VERSION ""

NS_ :

BS_:

BU_: CGW SCCM RDF ECM IC ACC ESP

BO_ 1046 NM_SCCM: 2 SCCM
 SG_ NM_SCCM_State : 8|8@1+ (1,0) [0|32] ""  RDF,IC,ESP,ECM,CGW,ACC
 SG_ NM_SCCM_ID : 0|8@1- (1,0) [0|0] ""  RDF,IC,ESP,ECM,CGW,ACC

BO_ 1045 NM_RDF: 2 RDF
 SG_ NM_RDF_State : 8|8@1+ (1,0) [0|32] ""  SCCM,RDF,IC,ESP,ECM,CGW,ACC
 SG_ NM_RDF_ID : 0|8@1+ (1,0) [0|255] ""  SCCM,RDF,IC,ESP,ECM,CGW,ACC

BO_ 1044 NM_IC: 2 IC
 SG_ NM_IC_State : 8|8@1+ (1,0) [0|32] ""  SCCM,RDF,ESP,ECM,CGW,ACC
 SG_ NM_IC_ID : 0|8@1+ (1,0) [0|255] ""  SCCM,RDF,ESP,ECM,CGW,ACC

BO_ 1029 NM_ESP: 2 ESP
 SG_ NM_ESP_State : 8|8@1+ (1,0) [0|32] ""  SCCM,RDF,IC,ECM,CGW,ACC
 SG_ NM_ESP_ID : 0|8@1+ (1,0) [0|255] ""  SCCM,RDF,IC,ECM,CGW,ACC

BO_ 1034 NM_ECM: 2 ECM
 SG_ NM_ECM_State : 8|8@1+ (1,0) [0|32] ""  SCCM,RDF,IC,ESP,ECM,CGW,ACC
 SG_ NM_ECM_ID : 0|8@1+ (1,0) [0|255] ""  SCCM,RDF,IC,ESP,ECM,CGW,ACC

BO_ 1024 NM_CGW: 2 CGW
 SG_ NM_CGW_State : 8|8@1+ (1,0) [0|32] ""  SCCM,RDF,IC,ESP,ECM,ACC
 SG_ NM_CGW_ID : 0|8@1+ (1,0) [0|255] ""  SCCM,RDF,IC,ESP,ECM,ACC

BO_ 1039 NM_ACC: 2 ACC
 SG_ NM_ACC_State : 8|8@1+ (1,0) [0|32] ""  SCCM,RDF,IC,ESP,ECM,CGW
 SG_ NM_ACC_ID : 0|8@1+ (1,0) [0|255] ""  SCCM,RDF,IC,ESP,ECM,CGW

BO_ 848 ECM_DIAG_RS_E2E_PR1: 32 ECM
 SG_ CAN_Frame_03_Signal_CRC : 0|8@1+ (1,0) [0|255] ""  CGW
 SG_ CAN_Frame_03_Signal_MC : 8|4@1+ (1,0) [0|15] ""  CGW
 SG_ CAN_Frame_03_Signal_I : 209|1@1+ (1,0) [0|1] ""  CGW
 SG_ CAN_Frame_03_Signal_H : 208|1@1+ (1,0) [0|1] ""  CGW
 SG_ CAN_Frame_03_Signal_G : 176|32@1- (1,0) [-2147483648|2147483647] ""  CGW
 SG_ CAN_Frame_03_Signal_F : 144|32@1- (1,0) [-2147483648|2147483647] ""  CGW
 SG_ CAN_Frame_03_Signal_E : 112|32@1- (1,0) [-2147483648|2147483647] ""  CGW
 SG_ CAN_Frame_03_Signal_D : 80|32@1- (1,0) [-2147483648|2147483647] ""  CGW
 SG_ CAN_Frame_03_Signal_C : 48|32@1- (1,0) [-2147483648|2147483647] ""  CGW
 SG_ CAN_Frame_03_Signal_B : 16|32@1- (0.1,0) [-214748364.8|214748364.7] "V"  CGW
 SG_ CAN_Frame_03_Signal_A : 12|4@1+ (1,0) [0|15] ""  CGW

BO_ 832 CGW_DIAG_RQ_E2E_PR1: 32 CGW
 SG_ CAN_Frame_02_Signal_MC : 8|4@1+ (1,0) [0|15] ""  SCCM,RDF,IC,ESP,ECM,ACC
 SG_ CAN_Frame_02_Signal_CRC : 0|8@1+ (1,0) [0|255] ""  SCCM,RDF,IC,ESP,ECM,ACC
 SG_ CAN_Frame_02_Signal_I : 209|1@1+ (1,0) [0|1] ""  SCCM,RDF,IC,ESP,ECM,ACC
 SG_ CAN_Frame_02_Signal_H : 208|1@1+ (1,0) [0|1] ""  SCCM,RDF,IC,ESP,ECM,ACC
 SG_ CAN_Frame_02_Signal_G : 176|32@1- (1,0) [-2147483648|2147483647] ""  SCCM,RDF,IC,ESP,ECM,ACC
 SG_ CAN_Frame_02_Signal_F : 144|32@1- (1,0) [-2147483648|2147483647] ""  SCCM,RDF,IC,ESP,ECM,ACC
 SG_ CAN_Frame_02_Signal_E : 112|32@1- (1,0) [-2147483648|2147483647] ""  SCCM,RDF,IC,ESP,ECM,ACC
 SG_ CAN_Frame_02_Signal_D : 80|32@1- (1,0) [-2147483648|2147483647] ""  SCCM,RDF,IC,ESP,ECM,ACC
 SG_ CAN_Frame_02_Signal_C : 48|32@1- (1,0) [-2147483648|2147483647] ""  SCCM,RDF,IC,ESP,ECM,ACC
 SG_ CAN_Frame_02_Signal_B : 16|32@1- (0.1,0) [-214748364.8|214748364.7] "V"  SCCM,RDF,IC,ESP,ECM,ACC
 SG_ CAN_Frame_02_Signal_A : 12|4@1+ (1,0) [0|15] ""  SCCM,RDF,IC,ESP,ECM,ACC

BO_ 801 CGW_DIAG_E2E_PR1: 32 CGW
 SG_ CAN_Frame_01_Signal_G : 192|32@1- (1,0) [-2147483648|2147483647] ""  SCCM,RDF,IC,ESP,ECM,ACC
 SG_ CAN_Frame_01_Signal_F : 160|32@1- (1,0) [-2147483648|2147483647] ""  SCCM,RDF,IC,ESP,ECM,ACC
 SG_ CAN_Frame_01_Signal_E : 128|32@1- (1,0) [-2147483648|2147483647] ""  SCCM,RDF,IC,ESP,ECM,ACC
 SG_ CAN_Frame_01_Signal_D : 96|32@1- (1,0) [-2147483648|2147483647] ""  SCCM,RDF,IC,ESP,ECM,ACC
 SG_ CAN_Frame_01_Signal_MC : 8|4@1+ (1,0) [0|15] ""  SCCM,RDF,IC,ESP,ECM,ACC
 SG_ CAN_Frame_01_Signal_CRC : 0|8@1+ (1,0) [0|255] ""  SCCM,RDF,IC,ESP,ECM,ACC
 SG_ CAN_Frame_01_Signal_C : 64|32@1- (1,0) [-2147483648|2147483647] ""  SCCM,RDF,IC,ESP,ECM,ACC
 SG_ CAN_Frame_01_Signal_B : 32|32@1- (0.1,0) [-214748364.8|214748364.7] "V"  SCCM,RDF,IC,ESP,ECM,ACC
 SG_ CAN_Frame_01_Signal_A : 16|16@1+ (1,0) [0|65535] ""  SCCM,RDF,IC,ESP,ECM,ACC

BO_ 315 SCCM_ACC_E2E_PR2: 12 SCCM
 SG_ SCCM_ACC_E2E_PR2_MC : 8|4@1+ (1,0) [0|15] ""  ACC
 SG_ SCCM_ACC_E2E_PR2_CRC : 0|8@1+ (1,0) [0|255] ""  ACC
 SG_ SCCM_st_ACCSpdUp10 : 72|8@1- (1,0) [0|0] ""  ACC
 SG_ SCCM_st_ACCSpdUp1 : 64|8@1+ (1,0) [0|0] ""  ACC
 SG_ SCCM_st_ACCSpdDn10 : 56|8@1- (1,0) [0|0] ""  ACC
 SG_ SCCM_st_ACCSpdDn1 : 48|8@1- (1,0) [0|0] ""  ACC
 SG_ SCCM_st_ACCDistUpRq : 40|8@1+ (1,0) [0|0] ""  ACC
 SG_ SCCM_st_ACCDistDnRq : 32|8@1- (1,0) [0|0] ""  ACC
 SG_ SCCM_st_ACCResume : 24|8@1+ (1,0) [0|3] ""  ACC
 SG_ SCCM_st_ACCOn : 16|8@1+ (1,0) [0|3] ""  ACC

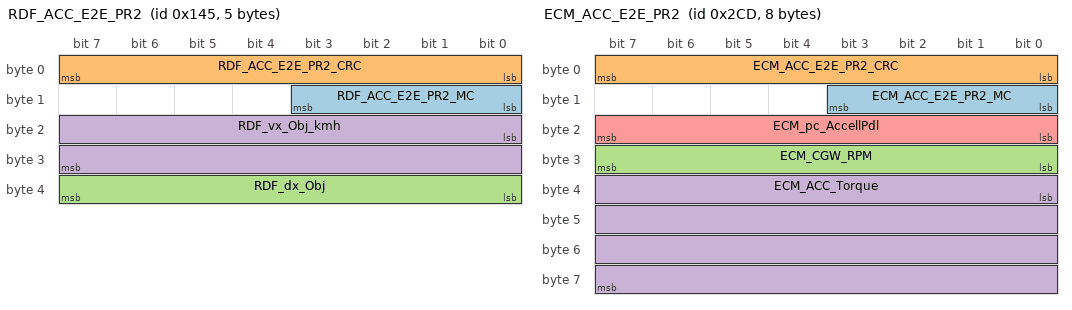
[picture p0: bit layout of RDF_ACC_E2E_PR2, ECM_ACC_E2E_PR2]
BO_ 325 RDF_ACC_E2E_PR2: 5 RDF
 SG_ RDF_ACC_E2E_PR2_MC : 8|4@1+ (1,0) [0|15] ""  ACC
 SG_ RDF_ACC_E2E_PR2_CRC : 0|8@1+ (1,0) [0|255] ""  ACC
 SG_ RDF_dx_Obj : 32|8@1+ (1,0) [0|255] "m"  ACC
 SG_ RDF_vx_Obj_kmh : 16|16@1+ (1,0) [0|255] "km/h"  ACC

BO_ 717 ECM_ACC_E2E_PR2: 8 ECM
 SG_ ECM_ACC_E2E_PR2_MC : 8|4@1+ (1,0) [0|15] ""  ACC
 SG_ ECM_ACC_E2E_PR2_CRC : 0|8@1+ (1,0) [0|255] ""  ACC
 SG_ ECM_CGW_RPM : 24|8@1+ (1,0) [0|10000] ""  CGW,ACC
 SG_ ECM_ACC_Torque : 32|32@1- (1,0) [-2147483648|2147483647] "Nm"  ACC
 SG_ ECM_pc_AccellPdl : 16|8@1- (1,0) [0|0] ""  ACC

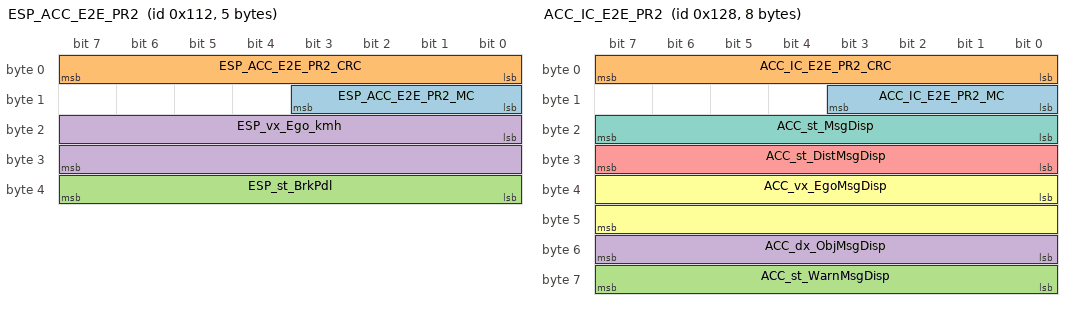
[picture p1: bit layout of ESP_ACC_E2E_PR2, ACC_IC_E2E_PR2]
BO_ 274 ESP_ACC_E2E_PR2: 5 ESP
 SG_ ESP_ACC_E2E_PR2_MC : 8|4@1+ (1,0) [0|15] ""  ACC
 SG_ ESP_ACC_E2E_PR2_CRC : 0|8@1+ (1,0) [0|255] ""  ACC
 SG_ ESP_st_BrkPdl : 32|8@1- (1,0) [0|0] ""  ACC
 SG_ ESP_vx_Ego_kmh : 16|16@1- (1,0) [0|255] ""  ACC

BO_ 296 ACC_IC_E2E_PR2: 8 ACC
 SG_ ACC_IC_E2E_PR2_MC : 8|4@1+ (1,0) [0|15] ""  IC
 SG_ ACC_IC_E2E_PR2_CRC : 0|8@1+ (1,0) [0|255] ""  IC
 SG_ ACC_st_WarnMsgDisp : 56|8@1- (1,0) [0|0] ""  IC
 SG_ ACC_dx_ObjMsgDisp : 48|8@1+ (1,0) [0|255] "m"  SCCM,IC
 SG_ ACC_st_DistMsgDisp : 24|8@1+ (1,0) [0|6] ""  IC
 SG_ ACC_vx_EgoMsgDisp : 32|16@1- (1,0) [0|0] ""  IC
 SG_ ACC_st_MsgDisp : 16|8@1+ (1,0) [0|4] ""  IC

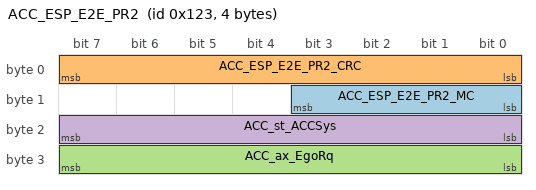
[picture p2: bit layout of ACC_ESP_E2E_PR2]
BO_ 291 ACC_ESP_E2E_PR2: 4 ACC
 SG_ ACC_ESP_E2E_PR2_MC : 8|4@1+ (1,0) [0|15] ""  ESP
 SG_ ACC_ESP_E2E_PR2_CRC : 0|8@1+ (1,0) [0|255] ""  ESP
 SG_ ACC_ax_EgoRq : 24|8@1- (1,0) [0|0] ""  ESP
 SG_ ACC_st_ACCSys : 16|8@1+ (1,0) [0|4] ""  ESP

CM_ "This example is generated by AKKA Gmbh& Co. KGaA for PROVEtech:RBS";
CM_ SG_ 848 CAN_Frame_03_Signal_CRC "CRC-Checksum according SAE J1850";
CM_ SG_ 848 CAN_Frame_03_Signal_MC "Messagecounter";
CM_ SG_ 832 CAN_Frame_02_Signal_MC "Messagecounter";
CM_ SG_ 832 CAN_Frame_02_Signal_CRC "CRC-Checksum according SAE J1850";
CM_ SG_ 801 CAN_Frame_01_Signal_MC "Messagecounter";
CM_ SG_ 801 CAN_Frame_01_Signal_CRC "CRC-Checksum according SAE J1850";
BA_DEF_  "Baudrate" INT 1 1000000;
BA_DEF_ BO_  "GenMsgChkConstant" HEX 0 4095;
BA_DEF_ BO_  "CANFD_BRS" ENUM  "0","1";
BA_DEF_  "Manufacturer" STRING ;
BA_DEF_  "NmMessageCount" INT 0 1024;
BA_DEF_ BU_  "NmStationAddress" INT 0 128;
BA_DEF_ BU_  "NmNode" ENUM  "no","yes";
BA_DEF_ BO_  "NmMessage" ENUM  "no","yes";
BA_DEF_  "NmBaseAddress" HEX 1024 1152;
BA_DEF_ BO_  "GenMsgCycleTimeFast" INT 0 16384;
BA_DEF_ BO_  "GenMsgPDUConstants" STRING ;
BA_DEF_  "Version_Year" INT 0 40;
BA_DEF_  "Version_Week" INT 1 52;
BA_DEF_  "Version_Month" INT 1 12;
BA_DEF_  "Version_Day" INT 1 31;
BA_DEF_  "DBName" STRING ;
BA_DEF_  "BusType" STRING ;
BA_DEF_ BO_  "VFrameFormat" ENUM  "StandardCAN","ExtendedCAN","reserved","J1939PG","reserved","reserved","reserved","reserved","reserved","reserved","reserved","reserved","reserved","reserved","StandardCAN_FD","ExtendedCAN_FD";
BA_DEF_ BO_  "GenMsgSendType" ENUM  "cyclicX","spontanX","cyclicIfActiveX","spontanWithDelay","cyclicAndSpontanX","cyclicAndSpontanWithDelay","spontanWithRepitition","cyclicIfActiveAndSpontanWD","cyclicIfActiveFast","cyclicWithRepeatOnDemand","none";
BA_DEF_ BO_  "GenMsgCycleTime" INT 0 65535;
BA_DEF_ BO_  "GenMsgDelayTime" INT 0 65535;
BA_DEF_ SG_  "GenSigStartValue" FLOAT 0 0;
BA_DEF_ SG_  "FlexKomSigName" STRING ;
BA_DEF_DEF_  "Baudrate" 1;
BA_DEF_DEF_  "GenMsgChkConstant" 0;
BA_DEF_DEF_  "CANFD_BRS" "1";
BA_DEF_DEF_  "Manufacturer" "AKKA GmbH & Co. KGaA";
BA_DEF_DEF_  "NmMessageCount" 1;
BA_DEF_DEF_  "NmStationAddress" 0;
BA_DEF_DEF_  "NmNode" "no";
BA_DEF_DEF_  "NmMessage" "no";
BA_DEF_DEF_  "NmBaseAddress" 1024;
BA_DEF_DEF_  "GenMsgCycleTimeFast" 0;
BA_DEF_DEF_  "GenMsgPDUConstants" "";
BA_DEF_DEF_  "Version_Year" 19;
BA_DEF_DEF_  "Version_Week" 1;
BA_DEF_DEF_  "Version_Month" 1;
BA_DEF_DEF_  "Version_Day" 1;
BA_DEF_DEF_  "DBName" "CAN_Demo_Box_Cluster";
BA_DEF_DEF_  "BusType" "CAN";
BA_DEF_DEF_  "VFrameFormat" "StandardCAN";
BA_DEF_DEF_  "GenMsgSendType" "cyclicX";
BA_DEF_DEF_  "GenMsgCycleTime" 0;
BA_DEF_DEF_  "GenMsgDelayTime" 0;
BA_DEF_DEF_  "GenSigStartValue" 0;
BA_DEF_DEF_  "FlexKomSigName" "";
BA_ "BusType" "CAN FD";
BA_ "NmMessageCount" 256;
BA_ "Baudrate" 500000;
BA_ "DBName" "ACC_Demo";
BA_ "NmNode" BU_ CGW 1;
BA_ "NmNode" BU_ SCCM 1;
BA_ "NmStationAddress" BU_ SCCM 22;
BA_ "NmNode" BU_ RDF 1;
BA_ "NmStationAddress" BU_ RDF 21;
BA_ "NmNode" BU_ ECM 1;
BA_ "NmStationAddress" BU_ ECM 10;
BA_ "NmNode" BU_ IC 1;
BA_ "NmStationAddress" BU_ IC 20;
BA_ "NmNode" BU_ ACC 1;
BA_ "NmStationAddress" BU_ ACC 15;
BA_ "NmNode" BU_ ESP 1;
BA_ "NmStationAddress" BU_ ESP 5;
BA_ "GenMsgSendType" BO_ 1046 1;
BA_ "NmMessage" BO_ 1046 1;
BA_ "VFrameFormat" BO_ 1046 14;
BA_ "NmMessage" BO_ 1045 1;
BA_ "GenMsgSendType" BO_ 1045 1;
BA_ "VFrameFormat" BO_ 1045 14;
BA_ "NmMessage" BO_ 1044 1;
BA_ "GenMsgSendType" BO_ 1044 1;
BA_ "VFrameFormat" BO_ 1044 14;
BA_ "NmMessage" BO_ 1029 1;
BA_ "GenMsgSendType" BO_ 1029 1;
BA_ "VFrameFormat" BO_ 1029 14;
BA_ "NmMessage" BO_ 1034 1;
BA_ "GenMsgSendType" BO_ 1034 1;
BA_ "VFrameFormat" BO_ 1034 14;
BA_ "NmMessage" BO_ 1024 1;
BA_ "GenMsgSendType" BO_ 1024 1;
BA_ "VFrameFormat" BO_ 1024 14;
BA_ "GenMsgSendType" BO_ 1039 1;
BA_ "NmMessage" BO_ 1039 1;
BA_ "VFrameFormat" BO_ 1039 14;
BA_ "GenMsgPDUConstants" BO_ 848 "0x11,0x11,0x11,0x11,0x11,0x11,0x11,0x11,0x11,0x11,0x11,0x11,0x11,0x11,0x11,0x11";
BA_ "GenMsgSendType" BO_ 848 5;
BA_ "GenMsgCycleTime" BO_ 848 500;
BA_ "GenMsgDelayTime" BO_ 848 20;
BA_ "GenMsgChkConstant" BO_ 848 17;
BA_ "VFrameFormat" BO_ 848 14;
BA_ "GenMsgPDUConstants" BO_ 832 "0x42,0x42,0x42,0x42,0x42,0x42,0x42,0x42,0x42,0x42,0x42,0x42,0x42,0x42,0x42,0x42";
BA_ "GenMsgSendType" BO_ 832 4;
BA_ "GenMsgCycleTime" BO_ 832 1000;
BA_ "GenMsgChkConstant" BO_ 832 66;
BA_ "GenMsgCycleTimeFast" BO_ 832 100;
BA_ "GenMsgDelayTime" BO_ 832 20;
BA_ "VFrameFormat" BO_ 832 14;
BA_ "GenMsgCycleTime" BO_ 801 100;
BA_ "GenMsgSendType" BO_ 801 5;
BA_ "GenMsgCycleTimeFast" BO_ 801 50;
BA_ "GenMsgPDUConstants" BO_ 801 "0x90,0x90,0x90,0x90,0x90,0x90,0x90,0x90,0x90,0x90,0x90,0x90,0x90,0x90,0x90,0x90";
BA_ "GenMsgChkConstant" BO_ 801 144;
BA_ "GenMsgDelayTime" BO_ 801 5;
BA_ "VFrameFormat" BO_ 801 14;
BA_ "GenMsgPDUConstants" BO_ 315 "0x34,0x56,0x29,0x59,0x79,0x82,0xAD,0x22,0x61,0x81,0x78,0x23,0x72,0xA3,0x26,0x04";
BA_ "GenMsgSendType" BO_ 315 5;
BA_ "GenMsgCycleTime" BO_ 315 20;
BA_ "GenMsgDelayTime" BO_ 315 10;
BA_ "VFrameFormat" BO_ 315 14;
BA_ "GenMsgPDUConstants" BO_ 325 "0x82,0x29,0x43,0x89,0x89,0x12,0xAD,0x22,0x61,0x81,0x89,0x18,0x23,0x48,0x78,0x52";
BA_ "GenMsgCycleTime" BO_ 325 10;
BA_ "GenMsgDelayTime" BO_ 325 5;
BA_ "VFrameFormat" BO_ 325 14;
BA_ "GenMsgCycleTimeFast" BO_ 717 20;
BA_ "GenMsgPDUConstants" BO_ 717 "0x79,0x62,0x533,0x99,0x89,0x13,0xAD,0x22,0x61,0x81,0x78,0x23,0x72,0xA8,0x76,0x09";
BA_ "GenMsgSendType" BO_ 717 5;
BA_ "GenMsgCycleTime" BO_ 717 50;
BA_ "GenMsgDelayTime" BO_ 717 10;
BA_ "VFrameFormat" BO_ 717 14;
BA_ "GenMsgCycleTimeFast" BO_ 274 10;
BA_ "GenMsgPDUConstants" BO_ 274 "0x94,0x27,0x73,0x92,0x49,0x12,0xAD,0x22,0x61,0x81,0x78,0x23,0x72,0x13,0x21,0x22";
BA_ "GenMsgSendType" BO_ 274 5;
BA_ "GenMsgCycleTime" BO_ 274 20;
BA_ "GenMsgDelayTime" BO_ 274 5;
BA_ "VFrameFormat" BO_ 274 14;
BA_ "GenMsgPDUConstants" BO_ 296 "0x59,0x67,0x53,0x89,0x89,0x12,0xAD,0x22,0x61,0x81,0x78,0x23,0x72,0xA3,0x26,0x04";
BA_ "GenMsgCycleTimeFast" BO_ 296 50;
BA_ "GenMsgSendType" BO_ 296 5;
BA_ "GenMsgCycleTime" BO_ 296 100;
BA_ "GenMsgDelayTime" BO_ 296 10;
BA_ "VFrameFormat" BO_ 296 14;
BA_ "GenMsgCycleTimeFast" BO_ 291 100;
BA_ "GenMsgPDUConstants" BO_ 291 "0x65,0x16,0x53,0x89,0x65,0x02,0xCD,0x22,0x61,0x81,0x14,0x23,0x78,0xA1,0x23,0x03";
BA_ "GenMsgSendType" BO_ 291 8;
BA_ "GenMsgCycleTime" BO_ 291 1000;
BA_ "VFrameFormat" BO_ 291 14;
BA_ "FlexKomSigName" SG_ 848 CAN_Frame_03_Signal_CRC "CAN_Frame_03_SignalGroup";
BA_ "GenSigStartValue" SG_ 848 CAN_Frame_03_Signal_CRC 255;
BA_ "FlexKomSigName" SG_ 848 CAN_Frame_03_Signal_MC "CAN_Frame_03_SignalGroup";
BA_ "GenSigStartValue" SG_ 848 CAN_Frame_03_Signal_I 1;
BA_ "FlexKomSigName" SG_ 848 CAN_Frame_03_Signal_I "CAN_Frame_03_SignalGroup";
BA_ "GenSigStartValue" SG_ 848 CAN_Frame_03_Signal_H 1;
BA_ "FlexKomSigName" SG_ 848 CAN_Frame_03_Signal_H "CAN_Frame_03_SignalGroup";
BA_ "GenSigStartValue" SG_ 848 CAN_Frame_03_Signal_G 63;
BA_ "FlexKomSigName" SG_ 848 CAN_Frame_03_Signal_G "CAN_Frame_03_SignalGroup";
BA_ "GenSigStartValue" SG_ 848 CAN_Frame_03_Signal_F 255;
BA_ "FlexKomSigName" SG_ 848 CAN_Frame_03_Signal_F "CAN_Frame_03_SignalGroup";
BA_ "GenSigStartValue" SG_ 848 CAN_Frame_03_Signal_E 255;
BA_ "FlexKomSigName" SG_ 848 CAN_Frame_03_Signal_E "CAN_Frame_03_SignalGroup";
BA_ "GenSigStartValue" SG_ 848 CAN_Frame_03_Signal_D 255;
BA_ "FlexKomSigName" SG_ 848 CAN_Frame_03_Signal_D "CAN_Frame_03_SignalGroup";
BA_ "GenSigStartValue" SG_ 848 CAN_Frame_03_Signal_C 255;
BA_ "FlexKomSigName" SG_ 848 CAN_Frame_03_Signal_C "CAN_Frame_03_SignalGroup";
BA_ "GenSigStartValue" SG_ 848 CAN_Frame_03_Signal_B 255;
BA_ "FlexKomSigName" SG_ 848 CAN_Frame_03_Signal_B "CAN_Frame_03_SignalGroup";
BA_ "GenSigStartValue" SG_ 848 CAN_Frame_03_Signal_A 15;
BA_ "FlexKomSigName" SG_ 848 CAN_Frame_03_Signal_A "CAN_Frame_03_SignalGroup";
BA_ "FlexKomSigName" SG_ 832 CAN_Frame_02_Signal_MC "CAN_Frame_02_SignalGroup";
BA_ "FlexKomSigName" SG_ 832 CAN_Frame_02_Signal_CRC "CAN_Frame_02_SignalGroup";
BA_ "GenSigStartValue" SG_ 832 CAN_Frame_02_Signal_CRC 255;
BA_ "GenSigStartValue" SG_ 832 CAN_Frame_02_Signal_I 1;
BA_ "FlexKomSigName" SG_ 832 CAN_Frame_02_Signal_I "CAN_Frame_02_SignalGroup";
BA_ "GenSigStartValue" SG_ 832 CAN_Frame_02_Signal_H 1;
BA_ "FlexKomSigName" SG_ 832 CAN_Frame_02_Signal_H "CAN_Frame_02_SignalGroup";
BA_ "GenSigStartValue" SG_ 832 CAN_Frame_02_Signal_G 63;
BA_ "FlexKomSigName" SG_ 832 CAN_Frame_02_Signal_G "CAN_Frame_02_SignalGroup";
BA_ "GenSigStartValue" SG_ 832 CAN_Frame_02_Signal_F 255;
BA_ "FlexKomSigName" SG_ 832 CAN_Frame_02_Signal_F "CAN_Frame_02_SignalGroup";
BA_ "GenSigStartValue" SG_ 832 CAN_Frame_02_Signal_E 255;
BA_ "FlexKomSigName" SG_ 832 CAN_Frame_02_Signal_E "CAN_Frame_02_SignalGroup";
BA_ "GenSigStartValue" SG_ 832 CAN_Frame_02_Signal_D 255;
BA_ "FlexKomSigName" SG_ 832 CAN_Frame_02_Signal_D "CAN_Frame_02_SignalGroup";
BA_ "GenSigStartValue" SG_ 832 CAN_Frame_02_Signal_C 255;
BA_ "FlexKomSigName" SG_ 832 CAN_Frame_02_Signal_C "CAN_Frame_02_SignalGroup";
BA_ "GenSigStartValue" SG_ 832 CAN_Frame_02_Signal_B 255;
BA_ "FlexKomSigName" SG_ 832 CAN_Frame_02_Signal_B "CAN_Frame_02_SignalGroup";
BA_ "GenSigStartValue" SG_ 832 CAN_Frame_02_Signal_A 15;
BA_ "FlexKomSigName" SG_ 832 CAN_Frame_02_Signal_A "CAN_Frame_02_SignalGroup";
BA_ "GenSigStartValue" SG_ 801 CAN_Frame_01_Signal_G 255;
BA_ "FlexKomSigName" SG_ 801 CAN_Frame_01_Signal_G "CAN_Frame_01_SignalGroup";
BA_ "GenSigStartValue" SG_ 801 CAN_Frame_01_Signal_F 255;
BA_ "FlexKomSigName" SG_ 801 CAN_Frame_01_Signal_F "CAN_Frame_01_SignalGroup";
BA_ "GenSigStartValue" SG_ 801 CAN_Frame_01_Signal_E 255;
BA_ "FlexKomSigName" SG_ 801 CAN_Frame_01_Signal_E "CAN_Frame_01_SignalGroup";
BA_ "GenSigStartValue" SG_ 801 CAN_Frame_01_Signal_D 255;
BA_ "FlexKomSigName" SG_ 801 CAN_Frame_01_Signal_D "CAN_Frame_01_SignalGroup";
BA_ "FlexKomSigName" SG_ 801 CAN_Frame_01_Signal_MC "CAN_Frame_01_SignalGroup";
BA_ "GenSigStartValue" SG_ 801 CAN_Frame_01_Signal_CRC 255;
BA_ "FlexKomSigName" SG_ 801 CAN_Frame_01_Signal_CRC "CAN_Frame_01_SignalGroup";
BA_ "GenSigStartValue" SG_ 801 CAN_Frame_01_Signal_C 255;
BA_ "FlexKomSigName" SG_ 801 CAN_Frame_01_Signal_C "CAN_Frame_01_SignalGroup";
BA_ "GenSigStartValue" SG_ 801 CAN_Frame_01_Signal_B 255;
BA_ "FlexKomSigName" SG_ 801 CAN_Frame_01_Signal_B "CAN_Frame_01_SignalGroup";
BA_ "GenSigStartValue" SG_ 801 CAN_Frame_01_Signal_A 15;
BA_ "FlexKomSigName" SG_ 801 CAN_Frame_01_Signal_A "CAN_Frame_01_SignalGroup";
BA_ "GenSigStartValue" SG_ 315 SCCM_st_ACCSpdUp10 3;
BA_ "GenSigStartValue" SG_ 315 SCCM_st_ACCSpdUp1 3;
BA_ "GenSigStartValue" SG_ 315 SCCM_st_ACCSpdDn10 3;
BA_ "GenSigStartValue" SG_ 315 SCCM_st_ACCSpdDn1 3;
BA_ "GenSigStartValue" SG_ 315 SCCM_st_ACCDistUpRq 3;
BA_ "GenSigStartValue" SG_ 315 SCCM_st_ACCDistDnRq 3;
BA_ "GenSigStartValue" SG_ 315 SCCM_st_ACCResume 3;
BA_ "GenSigStartValue" SG_ 315 SCCM_st_ACCOn 3;
BA_ "GenSigStartValue" SG_ 325 RDF_dx_Obj 255;
BA_ "GenSigStartValue" SG_ 274 ESP_st_BrkPdl 3;
BA_ "GenSigStartValue" SG_ 296 ACC_st_WarnMsgDisp 2;
BA_ "GenSigStartValue" SG_ 296 ACC_st_DistMsgDisp 6;
BA_ "GenSigStartValue" SG_ 296 ACC_st_MsgDisp 3;
BA_ "GenSigStartValue" SG_ 291 ACC_st_ACCSys 3;
VAL_ 1046 NM_SCCM_State 2 "SNA" 1 "Bus sleep" 0 "Bus active" ;
VAL_ 1045 NM_RDF_State 2 "SNA" 1 "Bus sleep" 0 "Bus active" ;
VAL_ 1044 NM_IC_State 2 "SNA" 1 "Bus sleep" 0 "Bus active" ;
VAL_ 1029 NM_ESP_State 2 "SNA" 1 "Bus sleep" 0 "Bus active" ;
VAL_ 1034 NM_ECM_State 2 "SNA" 1 "Bus sleep" 0 "Bus active" ;
VAL_ 1024 NM_CGW_State 2 "SNA" 1 "Bus sleep" 0 "Bus active" ;
VAL_ 1039 NM_ACC_State 2 "SNA" 1 "Bus sleep" 0 "Bus active" ;
VAL_ 315 SCCM_st_ACCSpdUp10 3 "ACC changing Spd: SNA" 2 "ACC changing Spd: + 10km/h Fail" 1 "ACC changing Spd: + 10km/h On" 0 "ACC changing Spd: + 10km/h Off" ;
VAL_ 315 SCCM_st_ACCSpdUp1 3 "ACC changing Spd: SNA" 2 "ACC changing Spd: + 10km/h Fail" 1 "ACC changing Spd: + 10km/h On" 0 "ACC changing Spd: + 10km/h Off" ;
VAL_ 315 SCCM_st_ACCSpdDn10 3 "ACC required Spd: SNA" 2 "ACC required Spd: 10km/h Fail" 1 "ACC required Spd: 10km/h On" 0 "ACC required Spd: 10km/h Off" ;
VAL_ 315 SCCM_st_ACCSpdDn1 3 "ACC required Spd: SNA" 2 "ACC required Spd: 1km/h Fail" 1 "ACC required Spd: 1km/h On" 0 "ACC required Spd: 1km/h Off" ;
VAL_ 315 SCCM_st_ACCDistUpRq 3 "ACC required dist: SNA" 2 "ACC required dist: + 1 Fail" 1 "ACC required dist: + 1 On" 0 "ACC required dist: + 1 Off" ;
VAL_ 315 SCCM_st_ACCDistDnRq 3 "ACC required Dist SNA" 2 "ACC required Dist Fail" 1 "ACC required Dist On" 0 "ACC required Dist Off" ;
VAL_ 315 SCCM_st_ACCResume 3 "Set ACC setting: SNA" 2 "Set ACC setting: Spd & Dist Fail" 1 "Set ACC setting: Spd & Dist On" 0 "Set ACC setting: Spd & Dist Off" ;
VAL_ 315 SCCM_st_ACCOn 3 "ACC status: SNA" 2 "ACC status: ACC not available" 1 "ACC status: ACC On" 0 "ACC status: ACC Off" ;
VAL_ 274 ESP_st_BrkPdl 3 "Brake pedal: SNA" 2 "Brake pedal: not defined" 1 "Brake pedal: Pdl pressed" 0 "Brake pedal: Pdl upstopped" ;
VAL_ 296 ACC_st_WarnMsgDisp 2 "IC crash status: SNA" 1 "IC crash status: Warning" 0 "IC crash status: No Warning" ;
VAL_ 296 ACC_st_DistMsgDisp 6 "IC required time distance: SNA" 5 "IC required time distance: NA" 4 "IC required time distance: 2s" 3 "IC required time distance: 1.75s" 2 "IC required time distance: 1.5s" 1 "IC required time distance: 1.25s" 0 "IC required time distance: 1s" ;
VAL_ 296 ACC_st_MsgDisp 3 "IC status: SNA" 2 "IC status: ACC Icon with colour" 1 "IC status: ACC Icon grey" 0 "IC status: No display" ;
VAL_ 291 ACC_st_ACCSys 3 "SNA" 2 "ACC Active" 1 "ACC On" 0 "ACC Off" ;
